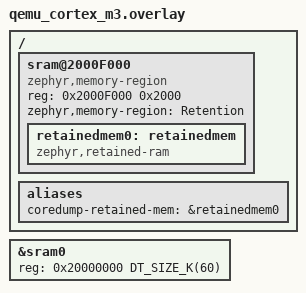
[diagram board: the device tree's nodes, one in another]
#include <common/mem.h>

/ {
	sram@2000F000 {
		compatible = "zephyr,memory-region", "mmio-sram";
		reg = <0x2000F000 0x2000>;
		zephyr,memory-region = "Retention";
		status = "okay";

		retainedmem0: retainedmem {
			compatible = "zephyr,retained-ram";
			status = "okay";
        };
    };

	aliases {
		coredump-retained-mem = &retainedmem0;
	};
};

&sram0 {
	reg = <0x20000000 DT_SIZE_K(60)>;
};
